# liliumSOC1_application register map
Vendor: Nordic Semiconductor; Series: liliumSOC1; File version: 1
CPU: CM33 r0p4, little endian, MPU, FPU, 3 interrupt priority bits, 480 interrupts
Registers are 32-bit, read-write, reset 0x0 unless marked. A register's access mark holds for its fields unless they carry their own. Offsets are from the block's base; [hi:lo] are bit positions; lines under a group give offsets from that group; {n}, {i} and the like mark numbered series.

## MPC_S — Memory Privilege Controller
Base 0x52001000
0x100 EVENTS_MEMACCERR — Memory Access Error event
  [0] EVENTS_MEMACCERR
    0=NotGenerated (Event not generated); 1=Generated (Event generated)
0x300 INTEN — Enable or disable interrupt
  [0] MEMACCERR — Enable or disable interrupt for event MEMACCERR
    0=Disabled; 1=Enabled
0x304 INTENSET — Enable interrupt
  [0] MEMACCERR — Write '1' to enable interrupt for event MEMACCERR
    on read: 0=Disabled (Read: Disabled); 1=Enabled (Read: Enabled) | on write: 1=Set (Enable)
0x308 INTENCLR — Disable interrupt
  [0] MEMACCERR — Write '1' to disable interrupt for event MEMACCERR
    on read: 0=Disabled (Read: Disabled); 1=Enabled (Read: Enabled) | on write: 1=Clear (Disable)
0x400 MEMACCERR group — Memory Access Error status registers
  0x00 ADDRESS ro — Target Address of Memory Access Error. Register content won't be changed as long as MEMACCERR event is active.
    [31:0] ADDRESS — Target address for erroneous access
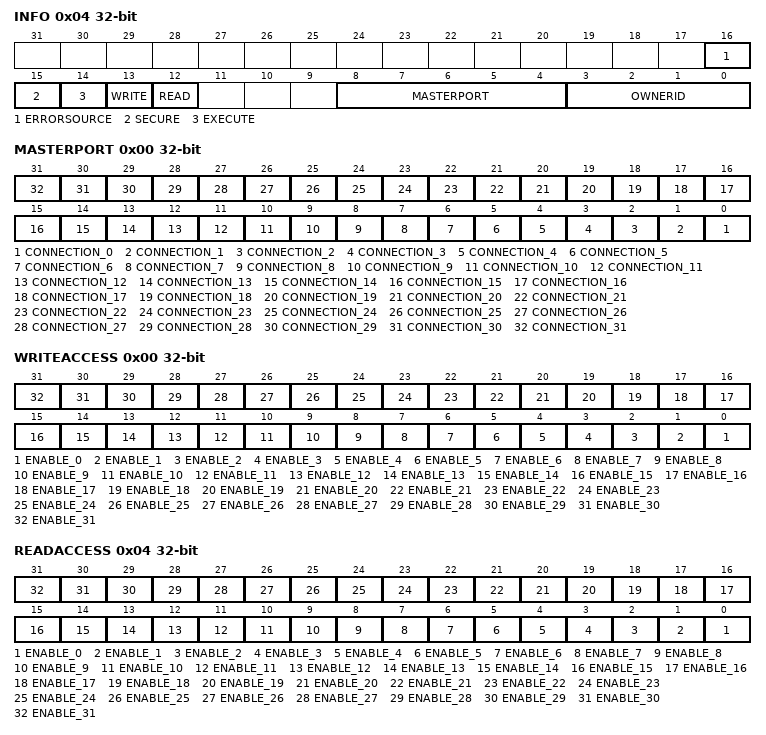
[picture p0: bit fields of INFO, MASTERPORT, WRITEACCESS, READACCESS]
  0x04 INFO ro — Access information for the transaction that triggered a memory access error. Register content won't be changed as long as MEMACCERR event is active.
    [16] ERRORSOURCE — Source of memory access error
      1=MPC (Error was triggered by MPC module); 0=Slave (Error was triggered by an AXI slave)
    [15] SECURE — Secure bit of bus access
      1=Set (Secure access bit was set); 0=NotSet (Secure access bit was not set)
    [14] EXECUTE — Execute bit of bus access
      1=Set (Execute access bit was set); 0=NotSet (Execute access bit was not set)
    [13] WRITE — Write bit of bus access
      1=Set (Write access bit was set); 0=NotSet (Write access bit was not set)
    [12] READ — Read bit of bus access
      1=Set (Read access bit was set); 0=NotSet (Read access bit was not set)
    [8:4] MASTERPORT — Master port where errorneous access is detected
    [3:0] OWNERID — Owner identifier of the errorneous access
0x410 GLOBALSLAVE group — Global slave master port connection information
  0x00 MASTERPORT — Global slave connection information for master port
    [n] CONNECTION_{n} (n=0..31) — Global slave connection information for master port
      0=Disabled (Master port {n} connection to global slave is disabled); 1=Enabled (Master port {n} connection to global slave is enabled)
  0x04 LOCK — Lock global slave registers
    [0] LOCK — Enable lock
      0=Disabled (Lock disabled.); 1=Enabled (Lock enabled.)
0x420 RTCHOKE group — Real time choke configuration for AXI master port
  0x00 WRITEACCESS — Enable AXI Write Address Channel Real Time Choke for master port
    [n] ENABLE_{n} (n=0..31) — Enable Real Time Choke for Write Address Channel
      0=Disable (Real Time Choke is disabled for master port {n} Write Address Channel); 1=Enable (Real Time Choke is enabled for master port {n} Write Address Channel)
  0x04 READACCESS — Enable AXI Read Address Channel Real Time Choke for master port
    [n] ENABLE_{n} (n=0..31) — Enable Real Time Choke for Read Address Channel
      0=Disable (Real Time Choke is disabled for master port {n} Read Address Channel); 1=Enable (Real Time Choke is enabled for master port {n} Read Address Channel)
  {0x60+4j} DELAY[{j}] (j=0..31) — Description collection: Real Time Choke delay value for slave number n
    [7:0] DELAY — Real Time Choke delay in bus clock cycles.
{0x600+0x10*i} REGION[{i}] (i=0..31) group — Memory region to slave decoding table
  0x00 CONFIG — Description cluster: Slave region n Configuration register
    [19:16] OWNERID — Region owner identifier.
    [15] SECATTR — Memory security mapping
      1=Secure (Memory is mapped in secure memory address space); 0=NonSecure (Memory is mapped in non-secure memory address space)
    [14] EXECUTE — Software execute
      0=NotAllowed (Software execution from region n is not allowed); 1=Allowed (Software execution from region n is allowed)
    [13] WRITE — Write access
      0=NotAllowed (Write access to region n is not allowed); 1=Allowed (Write access to region n is allowed)
    [12] READ — Read access
      0=NotAllowed (Read access to region n is not allowed); 1=Allowed (Read access to region n is allowed)
    [9] ENABLE — Region n enable
      0=Disabled (Region n is not used); 1=Enabled (Region n is used)
    [8] LOCK rw-once — Locks the region n setting
      0=Unlocked (Region n settings can be updated); 1=Locked (Region n settings can't be updated until next reset)
    [4:0] SLAVENUMBER — Target slave number for region n accesses. Slave number 0 is reserved for default slave
  0x04 STARTADDR — Description cluster: Region n start address
    [31:0] STARTADDR — Start address for memory region n Regions must be on a 4k memory boundary, lower 12 bits are ignored and read as zero
  0x08 ADDRMASK — Description cluster: Select which bits of the incoming address are compared against the STARTADDR
    [31:0] ADDRMASK — Address mask for memory region n Regions must be on a 4k memory boundary, lower 12 bits are ignored and read as zero
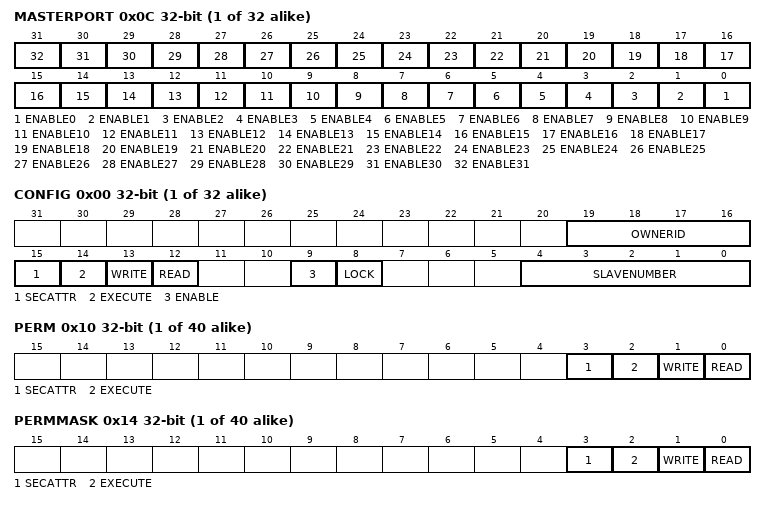
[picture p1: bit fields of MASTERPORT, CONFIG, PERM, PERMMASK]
  0x0C MASTERPORT — Description cluster: Region n local master enable
    [n] ENABLE{n} (n=0..31) — Enable region n for master port {n}
      0=Disable (Region n is disabled for master port {n}); 1=Enable (Region n is enabled for master port {n})
{0x800+0x20*i} OVERRIDE[{i}] (i=0..39) group — Special privilege tables
  0x00 CONFIG — Description cluster: Override region n Configuration register
    [12] SECUREMASK ro — Secure mask enable for Override region n
      0=Disabled (Mask is disabled for override region n); 1=Enabled (Mask is enabled for override region n)
    [10] SECDOMENABLE — Secure domain access enable for Override region n
      0=Disabled (Overriding of secure domain permissions is disabled for override region n); 1=Enabled (Overriding of secure domain permissions is enabled for override region n)
    [9] ENABLE — Enable Override region n
      0=Disabled (Override region n is not used); 1=Enabled (Override region n is used)
    [8] LOCK rw-once — Lock Override region n
      0=Unlocked (Override region n settings can be updated); 1=Locked (Override region n settings can't be updated until next reset)
    [4:0] SLAVENUMBER — Target slave number for override region n accesses. Slave number 0 is reserved for default slave
  0x04 STARTADDR — Description cluster: Override region n Start Address
    [31:0] STARTADDR — Start address for override region n Address must be on a 4k memory boundary, lower 12 bits are ignored and read as zero
  0x08 ENDADDR — Description cluster: Override region n End Address
    [31:0] ENDADDR — End address for override region n Address must be on a 4k memory boundary, lower 12 bits are ignored and read as zero
  0x0C OFFSET — Description cluster: Address offset value divided by 2 for override region n address re-map Offset will be left shifted before applying offset, to create a 33-bit signed integer.
    [31:0] OFFSET — Offset value Lower 11 bits are ignored
  0x10 PERM — Description cluster: Permission settings for override region n
    [3] SECATTR — Security mapping
      1=Secure (Override region n is mapped in secure memory address space); 0=NonSecure (Override region n is mapped in non-secure memory address space)
    [2] EXECUTE — Software execute
      0=NotAllowed (Software execution from override region n is not allowed); 1=Allowed (Software execution from override region n is allowed)
    [1] WRITE — Write access
      0=NotAllowed (Write access to override region n is not allowed); 1=Allowed (Write access to override region n is allowed)
    [0] READ — Read access
      0=NotAllowed (Read access to override region n is not allowed); 1=Allowed (Read access to override region n is allowed)
  0x14 PERMMASK — Description cluster: Masks permission setting fields from register OVERRIDE.PERM
    [3] SECATTR — Security mapping mask
      0=Masked (Permission setting SECATTR in OVERRIDE register will not be applied); 1=UnMasked (Permission setting SECATTR in OVERRIDE register will be applied)
    [2] EXECUTE — Execute mask
      0=Masked (Permission setting EXECUTE in OVERRIDE register will not be applied); 1=UnMasked (Permission setting EXECUTE in OVERRIDE register will be applied)
    [1] WRITE — Write mask
      0=Masked (Permission setting WRITE in OVERRIDE register will not be applied); 1=UnMasked (Permission setting WRITE in OVERRIDE register will be applied)
    [0] READ — Read mask
      0=Masked (Permission setting READ in OVERRIDE register will not be applied); 1=UnMasked (Permission setting READ in OVERRIDE register will be applied)
  0x18 OWNER — Description cluster: Owner for override region
    [3:0] OWNERID — owner identifier for override region n
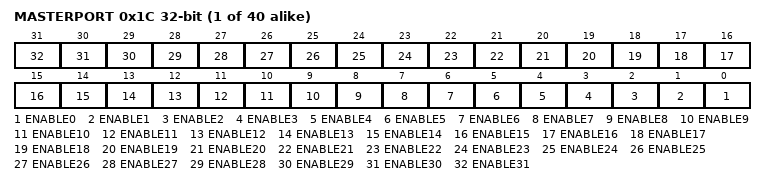
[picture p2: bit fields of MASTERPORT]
  0x1C MASTERPORT — Description cluster: Override region n local master enable
    [n] ENABLE{n} (n=0..31) — Enable override
      0=Disable (Override region n is disabled for master port {n}); 1=Enable (Override region n is enabled for master port {n})
